# N32L403 register map
Vendor: Nationstech Ltd.; File version: 1.0
Registers are 32-bit, read-write, reset 0x0 unless marked. A register's access mark holds for its fields unless they carry their own. Offsets are from the block's base; [hi:lo] are bit positions; {n}, {i} and the like mark numbered series; 'fields as' and 'values as' point back to an identical list.

## ADC — analog to digital converter
Base 0x40020800
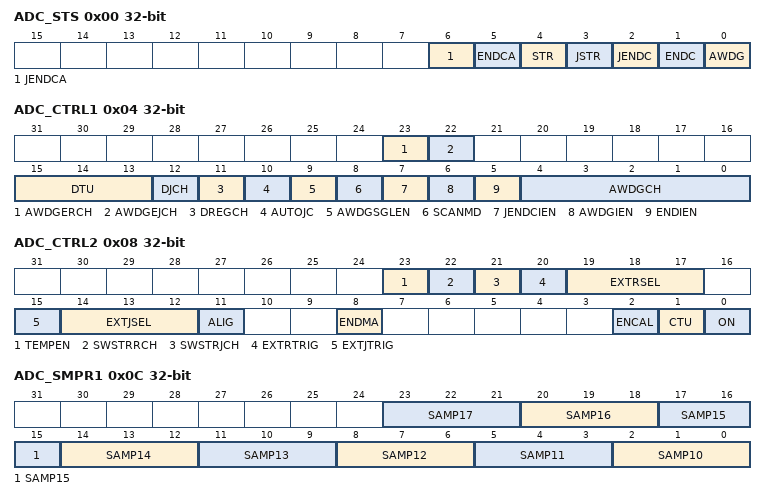
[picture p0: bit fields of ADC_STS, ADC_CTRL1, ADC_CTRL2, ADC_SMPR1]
0x00 ADC_STS
  [6] JENDCA, [5] ENDCA, [4] STR, [3] JSTR, [2] JENDC, [1] ENDC, [0] AWDG
0x04 ADC_CTRL1
  [23] AWDGERCH, [22] AWDGEJCH, [15:13] DTU, [12] DJCH, [11] DREGCH, [10] AUTOJC, [9] AWDGSGLEN, [8] SCANMD, [7] JENDCIEN, [6] AWDGIEN, [5] ENDIEN, [4:0] AWDGCH
0x08 ADC_CTRL2
  [23] TEMPEN, [22] SWSTRRCH, [21] SWSTRJCH, [20] EXTRTRIG, [19:17] EXTRSEL, [15] EXTJTRIG, [14:12] EXTJSEL, [11] ALIG, [8] ENDMA, [2] ENCAL, [1] CTU, [0] ON
0x0C ADC_SMPR1
  [3n-28:3n-30] SAMP{n} (n=10..17)
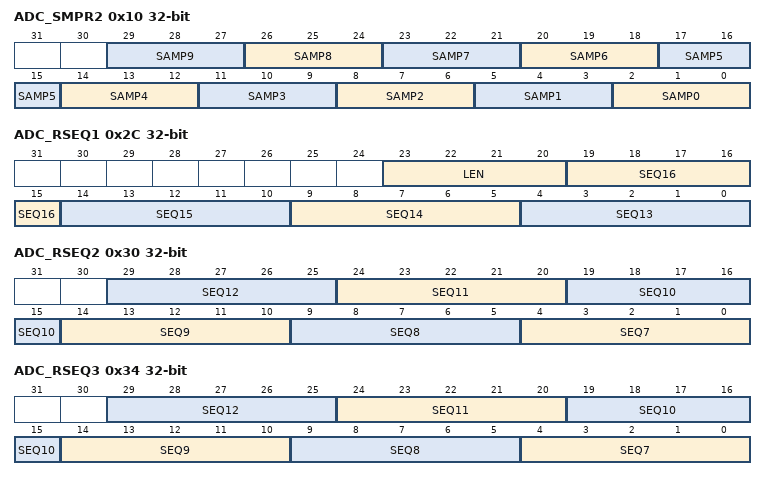
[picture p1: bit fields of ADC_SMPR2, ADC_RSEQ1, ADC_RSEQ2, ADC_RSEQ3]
0x10 ADC_SMPR2
  [3n+2:3n] SAMP{n} (n=0..9)
0x14 ADC_JOFFSET1
  [11:0] OFFSETJCH2
{0x10+4i} ADC_JOFFSET{i} (i=2..4)
  [11:0] OFFSETJCH{i}
0x24 ADC_WDGHIGH
  [15:0] HTH
0x28 ADC_WDGLOW
  [15:0] LTH
0x2C ADC_RSEQ1
  [23:20] LEN, [5n-61:5n-65] SEQ{n} (n=13..16)
0x30 ADC_RSEQ2
  [5n-31:5n-35] SEQ{n} (n=7..12)
0x34 ADC_RSEQ3
  [5n-31:5n-35] SEQ{n} (n=7..12)
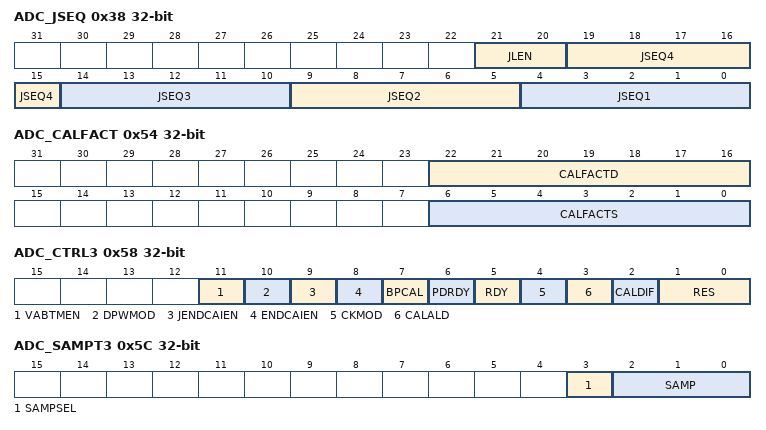
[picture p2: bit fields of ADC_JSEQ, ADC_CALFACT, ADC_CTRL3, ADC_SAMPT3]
0x38 ADC_JSEQ
  [21:20] JLEN, [5n-1:5n-5] JSEQ{n} (n=1..4)
{0x38+4i} ADC_JDAT{i} (i=1..4)
  [15:0] JDAT{i}
0x4C ADC_JDAT
  [15:0] JDAT
0x50 ADC_DIFSEL
  [18:1] DIFSEL
0x54 ADC_CALFACT
  [22:16] CALFACTD, [6:0] CALFACTS
0x58 ADC_CTRL3
  [11] VABTMEN, [10] DPWMOD, [9] JENDCAIEN, [8] ENDCAIEN, [7] BPCAL, [6] PDRDY, [5] RDY, [4] CKMOD, [3] CALALD, [2] CALDIF, [1:0] RES
0x5C ADC_SAMPT3
  [3] SAMPSEL, [2:0] SAMP

## COMP — comparator
Base 0x40002400
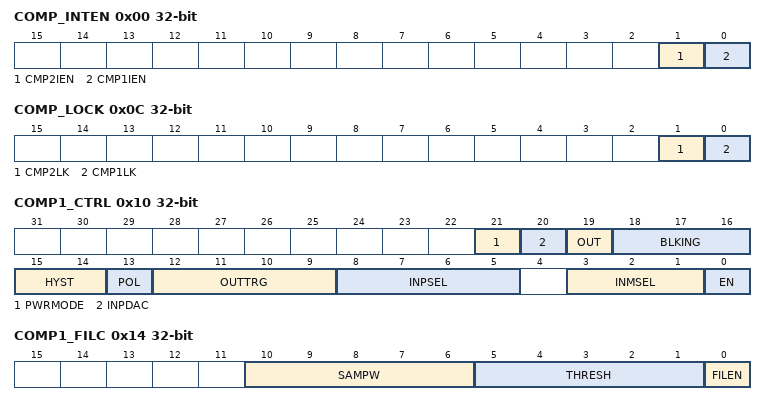
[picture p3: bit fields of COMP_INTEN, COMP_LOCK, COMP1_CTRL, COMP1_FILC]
0x00 COMP_INTEN
  [1] CMP2IEN, [0] CMP1IEN
0x04 COMP_LPCKSEL
  [0] LPCKSEL
0x08 COMP_WINMODE
  [0] CMP12MD
0x0C COMP_LOCK
  [1] CMP2LK, [0] CMP1LK
0x10 COMP1_CTRL
  [21] PWRMODE, [20] INPDAC, [19] OUT, [18:16] BLKING, [15:14] HYST, [13] POL, [12:9] OUTTRG, [8:5] INPSEL, [3:1] INMSEL, [0] EN
0x14 COMP1_FILC
  [10:6] SAMPW, [5:1] THRESH, [0] FILEN
0x18 COMP1_FILP
  [15:0] CLKPSC
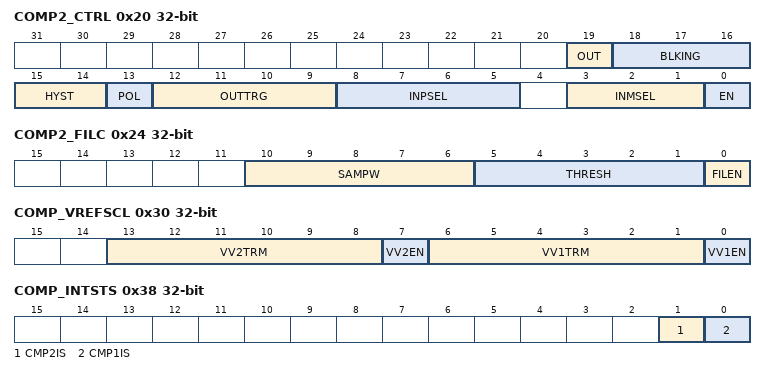
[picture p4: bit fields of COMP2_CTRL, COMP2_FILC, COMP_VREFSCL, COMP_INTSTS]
0x20 COMP2_CTRL
  [19] OUT, [18:16] BLKING, [15:14] HYST, [13] POL, [12:9] OUTTRG, [8:5] INPSEL, [3:1] INMSEL, [0] EN
0x24 COMP2_FILC
  [10:6] SAMPW, [5:1] THRESH, [0] FILEN
0x28 COMP2_FILP
  [15:0] CLKPSC
0x2C COMP2_OSEL
  [0] CMP2XO
0x30 COMP_VREFSCL
  [13:8] VV2TRM, [7] VV2EN, [6:1] VV1TRM, [0] VV1EN
0x34 COMP_TEST
  [0] EN
0x38 COMP_INTSTS
  [1] CMP2IS, [0] CMP1IS

## CRC — cyclic redundancy check
Base 0x40023000
0x00 CRC32DAT reset 0xFFFFFFFF
0x04 CRC32IDAT
  [7:0] CRC32IDAT
0x08 CRC32CTRL
  [0] RESET
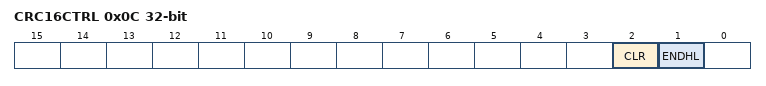
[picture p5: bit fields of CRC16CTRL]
0x0C CRC16CTRL
  [2] CLR, [1] ENDHL
0x10 CRC16DAT
  [7:0] CRC16DAT
0x14 CRC16D
  [15:0] CRC16D
0x18 LRC
  [7:0] LRCDAT

## DAC — digital to analog converter
Base 0x40007400
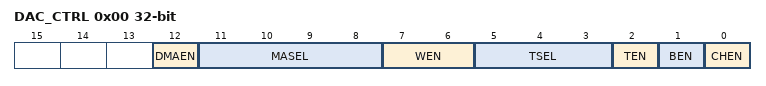
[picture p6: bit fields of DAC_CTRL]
0x00 DAC_CTRL
  [12] DMAEN, [11:8] MASEL, [7:6] WEN, [5:3] TSEL, [2] TEN, [1] BEN, [0] CHEN
0x04 DAC_SOTTR write
  [0] TR1EN
0x08 DAC_DR12CH
  [11:0] DACCHD
0x0C DAC_DL12CH
  [15:4] DACCHD
0x10 DAC_DR8CH
  [7:0] DACCHD
0x2C DAC_DATO
  [11:0] DACCHDO

## DBG — debug support for MCU
Base 0xE0042000
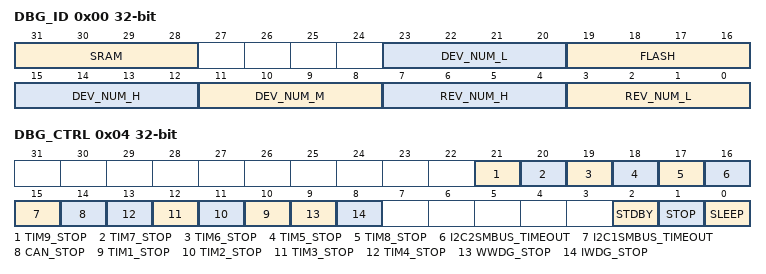
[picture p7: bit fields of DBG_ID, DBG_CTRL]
0x00 DBG_ID
  [31:28] SRAM, [23:20] DEV_NUM_L, [19:16] FLASH, [15:12] DEV_NUM_H, [11:8] DEV_NUM_M, [7:4] REV_NUM_H, [3:0] REV_NUM_L
0x04 DBG_CTRL
  [21] TIM9_STOP, [20] TIM7_STOP, [19] TIM6_STOP, [18] TIM5_STOP, [17] TIM8_STOP, [16] I2C2SMBUS_TIMEOUT, [15] I2C1SMBUS_TIMEOUT, [14] CAN_STOP, [n+9] TIM{n}_STOP (n=1..4), [9] WWDG_STOP, [8] IWDG_STOP, [2] STDBY, [1] STOP, [0] SLEEP

## DMA — Direct memory access controller
Base 0x40020000
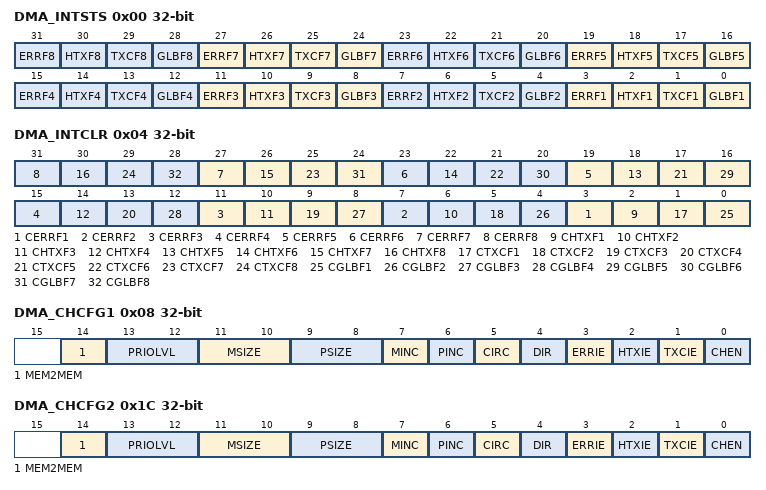
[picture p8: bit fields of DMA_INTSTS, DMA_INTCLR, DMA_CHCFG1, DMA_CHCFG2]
0x00 DMA_INTSTS
  [4n-1] ERRF{n} (n=1..8), [4n-2] HTXF{n} (n=1..8), [4n-3] TXCF{n} (n=1..8), [4n-4] GLBF{n} (n=1..8)
0x04 DMA_INTCLR
  [4n-1] CERRF{n} (n=1..8), [4n-2] CHTXF{n} (n=1..8), [4n-3] CTXCF{n} (n=1..8), [4n-4] CGLBF{n} (n=1..8)
0x08 DMA_CHCFG1
  [14] MEM2MEM, [13:12] PRIOLVL, [11:10] MSIZE, [9:8] PSIZE, [7] MINC, [6] PINC, [5] CIRC, [4] DIR, [3] ERRIE, [2] HTXIE, [1] TXCIE, [0] CHEN
0x0C DMA_TXNUM1
  [15:0] NDTX
0x10 DMA_PADDR1
  [31:0] ADDR
{0x0+0x14*i} DMA_MADDR{i} (i=1..8)
  [31:0] ADDR
{0x4+0x14*i} DMA_CHSEL{i} (i=1..8)
  [5:0] CH_SEL
0x1C DMA_CHCFG2
  fields as DMA_CHCFG1
0x20 DMA_TXNUM2
  [15:0] NDTX
0x24 DMA_PADDR2
  [31:0] ADDR
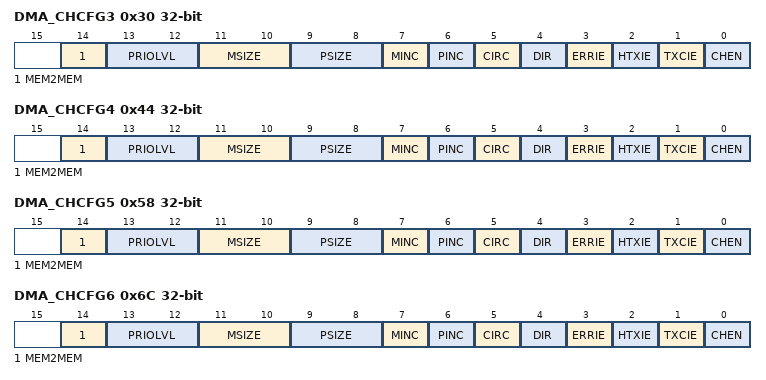
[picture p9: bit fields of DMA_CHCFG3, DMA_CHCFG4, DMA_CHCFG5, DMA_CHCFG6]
0x30 DMA_CHCFG3
  fields as DMA_CHCFG1
0x34 DMA_TXNUM3
  [15:0] NDTX
0x38 DMA_PADDR3
  [31:0] ADDR
0x44 DMA_CHCFG4
  fields as DMA_CHCFG1
0x48 DMA_TXNUM4
  [15:0] NDTX
0x4C DMA_PADDR4
  [31:0] ADDR
0x58 DMA_CHCFG5
  fields as DMA_CHCFG1
0x5C DMA_TXNUM5
  [15:0] NDTX
0x60 DMA_PADDR5
  [31:0] ADDR
0x6C DMA_CHCFG6
  fields as DMA_CHCFG1
0x70 DMA_TXNUM6
  [15:0] NDTX
0x74 DMA_PADDR6
  [31:0] ADDR
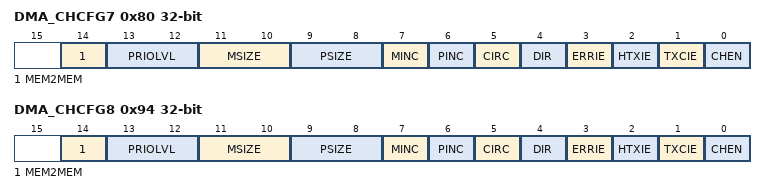
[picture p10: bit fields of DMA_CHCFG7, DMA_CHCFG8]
0x80 DMA_CHCFG7
  fields as DMA_CHCFG1
0x84 DMA_TXNUM7
  [15:0] NDTX
0x88 DMA_PADDR7
  [31:0] ADDR
0x94 DMA_CHCFG8
  fields as DMA_CHCFG1
0x98 DMA_TXNUM8
  [15:0] NDTX
0x9C DMA_PADDR8
  [31:0] ADDR
